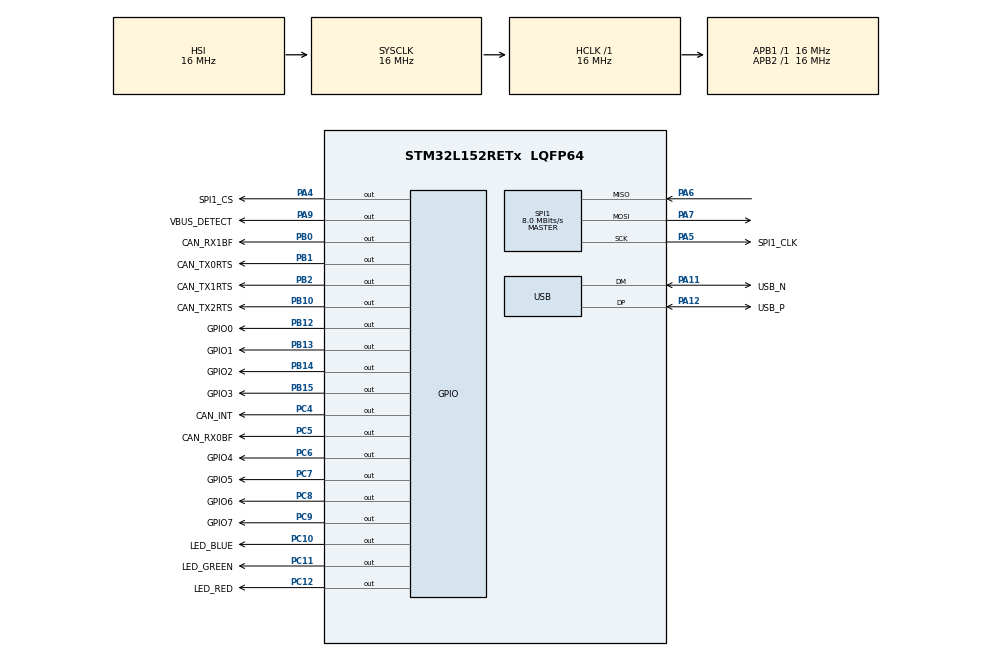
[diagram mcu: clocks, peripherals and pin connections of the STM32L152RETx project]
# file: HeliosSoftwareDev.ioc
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FREERTOS.Tasks01=defaultTask,24,128,StartDefaultTask,Default,NULL,Dynamic,NULL,NULL
Mcu.Family=STM32L1
Mcu.Name=STM32L152RETx
Mcu.Package=LQFP64
NVIC.PriorityGroup=NVIC_PRIORITYGROUP_4
NVIC.TIM2_IRQn=true\:15\:0\:false\:false\:true\:false\:false\:true\:true
NVIC.TimeBase=TIM2_IRQn
NVIC.TimeBaseIP=TIM2
NVIC.USB_LP_IRQn=true\:5\:0\:false\:false\:true\:true\:false\:true\:true
PA11.GPIO_Label=USB_N
PA11.Mode=Device
PA11.Signal=USB_DM
PA12.GPIO_Label=USB_P
PA12.Mode=Device
PA12.Signal=USB_DP
PA13.GPIO_Label=SWDIO
PA13.Mode=Trace_Asynchronous_SW
PA13.Signal=SYS_JTMS-SWDIO
PA14.GPIO_Label=SWCLK
PA14.Mode=Trace_Asynchronous_SW
PA14.Signal=SYS_JTCK-SWCLK
PA15.GPIO_Label=JTDI
PA15.Signal=SYS_JTDI
PA4.GPIO_Label=SPI1_CS
PA4.Signal=GPIO_Output
PA5.GPIO_Label=SPI1_CLK
PA5.Mode=Full_Duplex_Master
PA5.Signal=SPI1_SCK
PA6.Mode=Full_Duplex_Master
PA6.Signal=SPI1_MISO
PA7.Mode=Full_Duplex_Master
PA7.Signal=SPI1_MOSI
PA9.GPIO_Label=VBUS_DETECT
PA9.Signal=GPIO_Output
PB0.GPIO_Label=CAN_RX1BF
PB0.Signal=GPIO_Output
PB1.GPIO_Label=CAN_TX0RTS
PB1.Signal=GPIO_Output
PB10.GPIO_Label=CAN_TX2RTS
PB10.Signal=GPIO_Output
PB12.GPIO_Label=GPIO0
PB12.Signal=GPIO_Output
PB13.GPIO_Label=GPIO1
PB13.Signal=GPIO_Output
PB14.GPIO_Label=GPIO2
PB14.Signal=GPIO_Output
PB15.GPIO_Label=GPIO3
PB15.Signal=GPIO_Output
PB2.GPIO_Label=CAN_TX1RTS
PB2.Signal=GPIO_Output
PB3.GPIO_Label=JTDO
PB3.Mode=Trace_Asynchronous_SW
PB3.Signal=SYS_JTDO-TRACESWO
PC10.GPIO_Label=LED_BLUE
PC10.Signal=GPIO_Output
PC11.GPIO_Label=LED_GREEN
PC11.Signal=GPIO_Output
PC12.GPIO_Label=LED_RED
PC12.Signal=GPIO_Output
PC4.GPIO_Label=CAN_INT
PC4.Signal=GPIO_Output
PC5.GPIO_Label=CAN_RX0BF
PC5.Signal=GPIO_Output
PC6.GPIO_Label=GPIO4
PC6.Signal=GPIO_Output
PC7.GPIO_Label=GPIO5
PC7.Signal=GPIO_Output
PC8.GPIO_Label=GPIO6
PC8.Signal=GPIO_Output
PC9.GPIO_Label=GPIO7
PC9.Signal=GPIO_Output
PH0-OSC_IN.Mode=HSE-External-Oscillator
PH0-OSC_IN.Signal=RCC_OSC_IN
PH1-OSC_OUT.Mode=HSE-External-Oscillator
PH1-OSC_OUT.Signal=RCC_OSC_OUT
ProjectManager.HeapSize=0x200
ProjectManager.StackSize=0x400
ProjectManager.TargetToolchain=Makefile
RCC.48MHZClocksFreq_Value=48000000
RCC.AHBFreq_Value=16000000
RCC.APB1Freq_Value=16000000
RCC.APB1TimFreq_Value=16000000
RCC.APB2Freq_Value=16000000
RCC.APB2TimFreq_Value=16000000
RCC.HCLKFreq_Value=16000000
RCC.HSE_VALUE=24000000
RCC.HSI_VALUE=16000000
RCC.LSE_VALUE=32768
RCC.MSI_VALUE=2097000
RCC.PLLMUL=RCC_PLL_MUL4
RCC.SYSCLKFreq_VALUE=16000000
RCC.SYSCLKSource=RCC_SYSCLKSOURCE_HSI
RCC.VCOOutputFreq_Value=96000000
SPI1.BaudRatePrescaler=SPI_BAUDRATEPRESCALER_2
SPI1.CalculateBaudRate=8.0 MBits/s
SPI1.Direction=SPI_DIRECTION_2LINES
SPI1.Mode=SPI_MODE_MASTER
SPI1.VirtualType=VM_MASTER
USB_DEVICE.CLASS_NAME_FS=DFU
USB_DEVICE.VirtualMode=Dfu
USB_DEVICE.VirtualModeFS=Dfu_FS
VP_FREERTOS_VS_CMSIS_V2.Mode=CMSIS_V2
VP_SYS_VS_tim2.Mode=TIM2
VP_USB_DEVICE_VS_USB_DEVICE_DFU_FS.Mode=DFU_FS
board=custom

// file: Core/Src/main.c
/* USER CODE BEGIN Header */
/**
  ******************************************************************************
  * @file           : main.c
  * @brief          : Main program body
  ******************************************************************************
  * @attention
  *
  * Copyright (c) 2022 STMicroelectronics.
  * All rights reserved.
  *
  * This software is licensed under terms that can be found in the LICENSE file
  * in the root directory of this software component.
  * If no LICENSE file comes with this software, it is provided AS-IS.
  *
  ******************************************************************************
  */
/* USER CODE END Header */
#include "main.h"
#include "cmsis_os.h"
#include "usb_device.h"

/* USER CODE BEGIN Includes */
#include "ReadWriteEEPROMTask.h"
/* USER CODE END Includes */

SPI_HandleTypeDef hspi1;

/* Definitions for defaultTask */
osThreadId_t defaultTaskHandle;
const osThreadAttr_t defaultTask_attributes = {
  .name = "defaultTask",
  .stack_size = 128 * 4,
  .priority = (osPriority_t) osPriorityNormal,
};
/* USER CODE BEGIN PV */
osThreadId_t readWriteEEPROMTaskHandle;
const osThreadAttr_t readWriteEEPROMTask_attributes = {
  .name = "readWriteEEPROMTask",
  .stack_size = 128 * 4,
  .priority = (osPriority_t) osPriorityNormal,
};
/* USER CODE END PV */

void SystemClock_Config(void);
static void MX_GPIO_Init(void);
static void MX_SPI1_Init(void);
void StartDefaultTask(void *argument);

int main(void)
{

  /* MCU Configuration--------------------------------------------------------*/

  /* Reset of all peripherals, Initializes the Flash interface and the Systick. */
  HAL_Init();

  /* Configure the system clock */
  SystemClock_Config();

  /* Initialize all configured peripherals */
  MX_GPIO_Init();
  MX_SPI1_Init();

  /* Init scheduler */
  osKernelInitialize();

  /* Create the thread(s) */
  /* creation of defaultTask */
  defaultTaskHandle = osThreadNew(StartDefaultTask, NULL, &defaultTask_attributes);

  /* USER CODE BEGIN RTOS_THREADS */
  readWriteEEPROMTaskHandle = osThreadNew((osThreadFunc_t)readWriteEEPROMTask, NULL, &readWriteEEPROMTask_attributes);
  /* USER CODE END RTOS_THREADS */

  /* Start scheduler */
  osKernelStart();

/* We should never get here as control is now taken by the scheduler */
  /* Infinite loop */
  while (1)
  {

  }
}

void SystemClock_Config(void)
{
  RCC_OscInitTypeDef RCC_OscInitStruct = {0};
  RCC_ClkInitTypeDef RCC_ClkInitStruct = {0};

  /** Configure the main internal regulator output voltage
  */
  __HAL_PWR_VOLTAGESCALING_CONFIG(PWR_REGULATOR_VOLTAGE_SCALE1);

  /** Initializes the RCC Oscillators according to the specified parameters
  * in the RCC_OscInitTypeDef structure.
  */
  RCC_OscInitStruct.OscillatorType = RCC_OSCILLATORTYPE_HSI|RCC_OSCILLATORTYPE_HSE;
  RCC_OscInitStruct.HSEState = RCC_HSE_ON;
  RCC_OscInitStruct.HSIState = RCC_HSI_ON;
  RCC_OscInitStruct.HSICalibrationValue = RCC_HSICALIBRATION_DEFAULT;
  RCC_OscInitStruct.PLL.PLLState = RCC_PLL_ON;
  RCC_OscInitStruct.PLL.PLLSource = RCC_PLLSOURCE_HSE;
  RCC_OscInitStruct.PLL.PLLMUL = RCC_PLL_MUL4;
  RCC_OscInitStruct.PLL.PLLDIV = RCC_PLL_DIV2;
  if (HAL_RCC_OscConfig(&RCC_OscInitStruct) != HAL_OK)
  {
    Error_Handler();
  }

  /** Initializes the CPU, AHB and APB buses clocks
  */
  RCC_ClkInitStruct.ClockType = RCC_CLOCKTYPE_HCLK|RCC_CLOCKTYPE_SYSCLK
                              |RCC_CLOCKTYPE_PCLK1|RCC_CLOCKTYPE_PCLK2;
  RCC_ClkInitStruct.SYSCLKSource = RCC_SYSCLKSOURCE_HSI;
  RCC_ClkInitStruct.AHBCLKDivider = RCC_SYSCLK_DIV1;
  RCC_ClkInitStruct.APB1CLKDivider = RCC_HCLK_DIV1;
  RCC_ClkInitStruct.APB2CLKDivider = RCC_HCLK_DIV1;

  if (HAL_RCC_ClockConfig(&RCC_ClkInitStruct, FLASH_LATENCY_0) != HAL_OK)
  {
    Error_Handler();
  }
}

static void MX_SPI1_Init(void)
{

  /* SPI1 parameter configuration*/
  hspi1.Instance = SPI1;
  hspi1.Init.Mode = SPI_MODE_MASTER;
  hspi1.Init.Direction = SPI_DIRECTION_2LINES;
  hspi1.Init.DataSize = SPI_DATASIZE_8BIT;
  hspi1.Init.CLKPolarity = SPI_POLARITY_LOW;
  hspi1.Init.CLKPhase = SPI_PHASE_1EDGE;
  hspi1.Init.NSS = SPI_NSS_SOFT;
  hspi1.Init.BaudRatePrescaler = SPI_BAUDRATEPRESCALER_2;
  hspi1.Init.FirstBit = SPI_FIRSTBIT_MSB;
  hspi1.Init.TIMode = SPI_TIMODE_DISABLE;
  hspi1.Init.CRCCalculation = SPI_CRCCALCULATION_DISABLE;
  hspi1.Init.CRCPolynomial = 10;
  if (HAL_SPI_Init(&hspi1) != HAL_OK)
  {
    Error_Handler();
  }

}

static void MX_GPIO_Init(void)
{
  GPIO_InitTypeDef GPIO_InitStruct = {0};

  /* GPIO Ports Clock Enable */
  __HAL_RCC_GPIOH_CLK_ENABLE();
  __HAL_RCC_GPIOA_CLK_ENABLE();
  __HAL_RCC_GPIOC_CLK_ENABLE();
  __HAL_RCC_GPIOB_CLK_ENABLE();

  /*Configure GPIO pin Output Level */
  HAL_GPIO_WritePin(GPIOA, SPI1_CS_Pin|VBUS_DETECT_Pin, GPIO_PIN_RESET);

  /*Configure GPIO pin Output Level */
  HAL_GPIO_WritePin(GPIOC, CAN_INT_Pin|CAN_RX0BF_Pin|GPIO4_Pin|GPIO5_Pin
                          |GPIO6_Pin|GPIO7_Pin|LED_BLUE_Pin|LED_GREEN_Pin
                          |LED_RED_Pin, GPIO_PIN_RESET);

  /*Configure GPIO pin Output Level */
  HAL_GPIO_WritePin(GPIOB, CAN_RX1BF_Pin|CAN_TX0RTS_Pin|CAN_TX1RTS_Pin|CAN_TX2RTS_Pin
                          |GPIO0_Pin|GPIO1_Pin|GPIO2_Pin|GPIO3_Pin, GPIO_PIN_RESET);

  /*Configure GPIO pins : SPI1_CS_Pin VBUS_DETECT_Pin */
  GPIO_InitStruct.Pin = SPI1_CS_Pin|VBUS_DETECT_Pin;
  GPIO_InitStruct.Mode = GPIO_MODE_OUTPUT_PP;
  GPIO_InitStruct.Pull = GPIO_NOPULL;
  GPIO_InitStruct.Speed = GPIO_SPEED_FREQ_LOW;
  HAL_GPIO_Init(GPIOA, &GPIO_InitStruct);

  /*Configure GPIO pins : CAN_INT_Pin CAN_RX0BF_Pin GPIO4_Pin GPIO5_Pin
                           GPIO6_Pin GPIO7_Pin LED_BLUE_Pin LED_GREEN_Pin
                           LED_RED_Pin */
  GPIO_InitStruct.Pin = CAN_INT_Pin|CAN_RX0BF_Pin|GPIO4_Pin|GPIO5_Pin
                          |GPIO6_Pin|GPIO7_Pin|LED_BLUE_Pin|LED_GREEN_Pin
                          |LED_RED_Pin;
  GPIO_InitStruct.Mode = GPIO_MODE_OUTPUT_PP;
  GPIO_InitStruct.Pull = GPIO_NOPULL;
  GPIO_InitStruct.Speed = GPIO_SPEED_FREQ_LOW;
  HAL_GPIO_Init(GPIOC, &GPIO_InitStruct);

  /*Configure GPIO pins : CAN_RX1BF_Pin CAN_TX0RTS_Pin CAN_TX1RTS_Pin CAN_TX2RTS_Pin
                           GPIO0_Pin GPIO1_Pin GPIO2_Pin GPIO3_Pin */
  GPIO_InitStruct.Pin = CAN_RX1BF_Pin|CAN_TX0RTS_Pin|CAN_TX1RTS_Pin|CAN_TX2RTS_Pin
                          |GPIO0_Pin|GPIO1_Pin|GPIO2_Pin|GPIO3_Pin;
  GPIO_InitStruct.Mode = GPIO_MODE_OUTPUT_PP;
  GPIO_InitStruct.Pull = GPIO_NOPULL;
  GPIO_InitStruct.Speed = GPIO_SPEED_FREQ_LOW;
  HAL_GPIO_Init(GPIOB, &GPIO_InitStruct);

}

void StartDefaultTask(void *argument)
{
  /* init code for USB_DEVICE */
  MX_USB_DEVICE_Init();
  for(;;)
  {
    osDelay(1);
  }
}

void HAL_TIM_PeriodElapsedCallback(TIM_HandleTypeDef *htim)
{
  if (htim->Instance == TIM2) {
    HAL_IncTick();
  }
}

void Error_Handler(void)
{
  __disable_irq();
  while (1)
  {
  }
}
